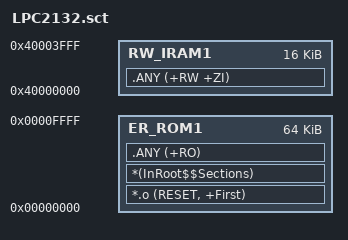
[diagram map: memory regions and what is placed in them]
; *************************************************************
; *** Scatter-Loading Description File for LPC2103          ***
; *************************************************************

LR_ROM1 0x00000000 0x00010000
 { ; load region size_region
   ER_ROM1 0x00000000 0x00010000
    { ; load address = execution address
      *.o (RESET, +First)
      *(InRoot$$Sections)
      .ANY (+RO)
    }
   RW_IRAM1 0x40000000 0x00004000
    { ; RW data
      .ANY (+RW +ZI)
    }
 }

